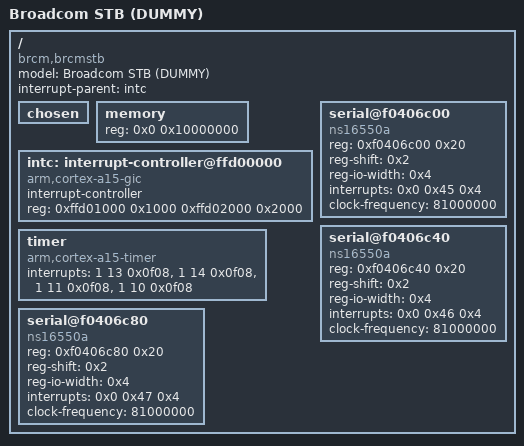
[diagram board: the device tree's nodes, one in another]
/dts-v1/;

/ {
	model = "Broadcom STB (DUMMY)";
	compatible = "brcm,brcmstb";
	#address-cells = <0x1>;
	#size-cells = <0x1>;
	interrupt-parent = <&intc>;

	chosen {
	};

	memory {
		device_type = "memory";
		reg = <0x0 0x10000000>;
	};

	intc: interrupt-controller@ffd00000 {
		compatible = "arm,cortex-a15-gic";
		interrupt-controller;
		#interrupt-cells = <0x3>;
		reg = <0xffd01000 0x1000 0xffd02000 0x2000>;
	};

	timer {
		compatible = "arm,cortex-a15-timer",
			     "arm,armv7-timer";
		interrupts = <1 13 0x0f08>,
			     <1 14 0x0f08>,
			     <1 11 0x0f08>,
			     <1 10 0x0f08>;
	};

	serial@f0406c00 {
		compatible = "ns16550a";
		reg = <0xf0406c00 0x20>;
		reg-shift = <0x2>;
		reg-io-width = <0x4>;
		interrupts = <0x0 0x45 0x4>;
		clock-frequency = <81000000>;
	};

	serial@f0406c40 {
		compatible = "ns16550a";
		reg = <0xf0406c40 0x20>;
		reg-shift = <0x2>;
		reg-io-width = <0x4>;
		interrupts = <0x0 0x46 0x4>;
		clock-frequency = <81000000>;
	};

	serial@f0406c80 {
		compatible = "ns16550a";
		reg = <0xf0406c80 0x20>;
		reg-shift = <0x2>;
		reg-io-width = <0x4>;
		interrupts = <0x0 0x47 0x4>;
		clock-frequency = <81000000>;
	};
};
